VERSION ""

NS_ :

BS_:

BU_: RADAR

BO_ 512 Write_RadarConfig: 8 RADAR
 SG_ MaxDistance_Valid : 0|1@1+ (1,0) [0|1] "Valid" Vector__XXX
 SG_ SensorID_Valid : 1|1@1+ (1,0) [0|1] "Valid" Vector__XXX
 SG_ RadarPower_Valid : 2|1@1+ (1,0) [0|1] "Valid" Vector__XXX
 SG_ OutputType_Valid : 3|1@1+ (1,0) [0|1] "Valid" Vector__XXX
 SG_ SendQuality_Valid : 4|1@1+ (1,0) [0|1] "Valid" Vector__XXX
 SG_ SendExtInfo_Valid : 5|1@1+ (1,0) [0|1] "Valid" Vector__XXX
 SG_ SortIndex_Valid : 6|1@1+ (1,0) [0|1] "Valid" Vector__XXX
 SG_ StoreInNvm_Valid : 7|1@1+ (1,0) [0|1] "Valid" Vector__XXX
 SG_ MaxDistance : 15|10@0+ (1,0) [0|2048] "" XXX
 SG_ SensorID : 32|3@1+ (1,0) [0|7] "ID" Vector__XXX
 SG_ OutputType : 35|2@1+ (1,0) [0|2] "Output Type" Vector__XXX
 SG_ RadarPower : 37|3@1+ (1,0) [0|7] "Power Mode" Vector__XXX
 SG_ SendQuality : 42|1@1+ (1,0) [0|1] "Quality Active" Vector__XXX
 SG_ SendExtInfo : 43|1@1+ (1,0) [0|1] "Extended Info Active" Vector__XXX
 SG_ SortIndex : 44|3@1+ (1,0) [0|7] "Sort Index" Vector__XXX
 SG_ StoreNVM : 47|1@1+ (1,0) [0|1] "Store in NVM" Vector__XXX
 SG_ RCS_Threshold_Valid : 48|1@1+ (1,0) [0|1] "RCS Threshold Valid" Vector__XXX
 SG_ RCS_Threshold : 49|3@1+ (1,0) [0|7] "RCS Threshold" Vector__XXX
 SG_ BaudRate_Valid : 60|1@1+ (1,0) [0|1] "Baud Rate Valid" Vector__XXX
 SG_ BaudRate : 61|3@1+ (1,0) [0|7] "Baud Rate" Vector__XXX

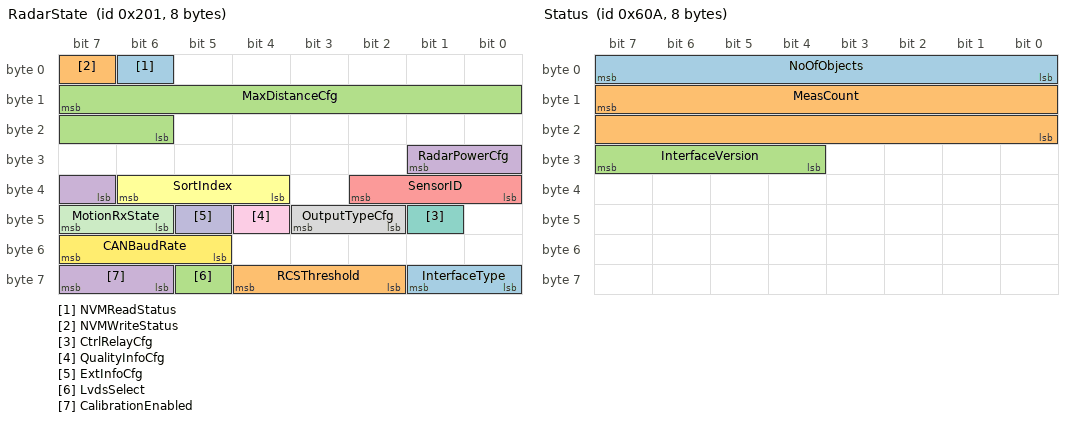
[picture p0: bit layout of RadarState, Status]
BO_ 513 RadarState: 8 RADAR
 SG_ NVMReadStatus : 6|1@0+ (1,0) [0|1] "" XXX
 SG_ NVMWriteStatus : 7|1@0+ (1,0) [0|1] "" XXX
 SG_ MaxDistanceCfg : 15|10@0+ (2,0) [0|2046] "m" XXX
 SG_ RadarPowerCfg : 25|3@0+ (1,0) [0|7] "" XXX
 SG_ SensorID : 34|3@0+ (1,0) [0|7] "" XXX
 SG_ SortIndex : 38|3@0+ (1,0) [0|7] "" XXX
 SG_ CtrlRelayCfg : 41|1@0+ (1,0) [0|1] "" XXX
 SG_ OutputTypeCfg : 43|2@0+ (1,0) [0|3] "" XXX
 SG_ QualityInfoCfg : 44|1@0+ (1,0) [0|1] "" XXX
 SG_ ExtInfoCfg : 45|1@0+ (1,0) [0|1] "" XXX
 SG_ MotionRxState : 46|2@1+ (1,0) [0|3] "" XXX
 SG_ CANBaudRate : 55|3@0+ (1,0) [0|7] "" XXX
 SG_ InterfaceType : 57|2@0+ (1,0) [0|3] "" XXX
 SG_ RCSThreshold : 58|3@1+ (1,0) [0|7] "" XXX
 SG_ LvdsSelect : 61|1@0+ (1,0) [0|1] "" XXX
 SG_ CalibrationEnabled : 63|2@0+ (1,0) [0|3] "" XXX

BO_ 1546 Status: 8 RADAR
 SG_ NoOfObjects : 7|8@0+ (1,0) [0|255] "" XXX
 SG_ MeasCount : 15|16@0+ (1,0) [0|65535] "" XXX
 SG_ InterfaceVersion : 31|4@0+ (1,0) [0|15] "" XXX

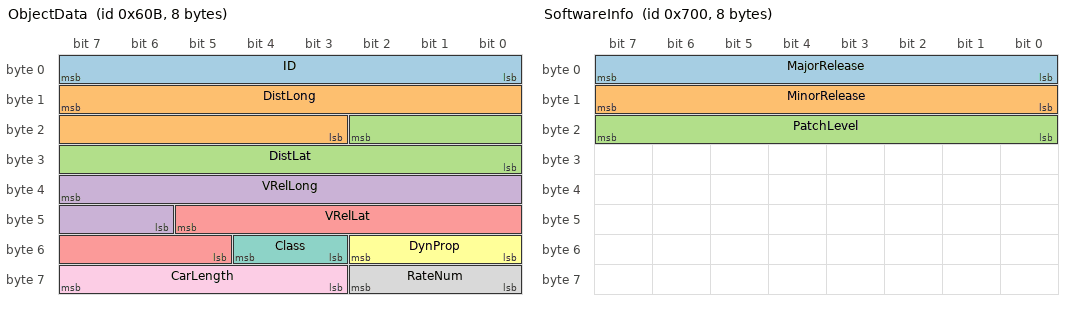
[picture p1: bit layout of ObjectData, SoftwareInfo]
BO_ 1547 ObjectData: 8 RADAR
 SG_ ID : 7|8@0+ (1,0) [0|255] "" XXX
 SG_ DistLong : 15|13@0+ (0.2,-500) [-500|1138.2] "m" XXX
 SG_ DistLat : 18|11@0+ (0.2,-204.6) [-204.6|204.8] "m" XXX
 SG_ VRelLong : 39|10@0+ (0.25,-128) [-128|127.75] "m/s" XXX
 SG_ VRelLat : 45|9@0+ (0.25,-64) [-64|63.75] "m/s" XXX
 SG_ DynProp : 50|3@0+ (1,0) [0|7] "" XXX
 SG_ Class : 52|2@0+ (1,0) [0|3] "" XXX
 SG_ RateNum : 58|3@0+ (1,0) [0|7] "" XXX
 SG_ CarLength : 63|5@0+ (0,0) [-64|63.75] "m" XXX

BO_ 1792 SoftwareInfo: 8 RADAR
 SG_ MajorRelease : 7|8@0+ (1,0) [0|255] "" XXX
 SG_ MinorRelease : 15|8@0+ (1,0) [0|255] "" XXX
 SG_ PatchLevel : 23|8@0+ (1,0) [0|255] "" XXX

CM_ SG_ 512 LVDS "Resereved";
CM_ SG_ 512 CalibrationEnabled "Reserved";
CM_ SG_ 512 CalibrationValid "Reserved";
CM_ BO_ 1547 "Object detection and tracking information";
CM_ SG_ 1547 RateNum "Target Lane Number";
VAL_ 513 NVMReadStatus 0 "Failed" 1 "Successful";
VAL_ 513 NVMWriteStatus 0 "Failed" 1 "Successful";
VAL_ 513 RadarPowerCfg 0 "Standard" 1 "-3dB Gain" 2 "-6dB Gain" 3 "-9dB Gain";
VAL_ 513 SortIndex 0 "No Sorting" 1 "Sort By Range" 2 "Sort By RCS";
VAL_ 513 CtrlRelayCfg 0 "Off" 1 "On";
VAL_ 513 OutputTypeCfg 0 "None" 1 "Objects" 2 "Clusters";
VAL_ 513 QualityInfoCfg 0 "Off" 1 "On";
VAL_ 513 ExtInfoCfg 0 "Off" 1 "On";
VAL_ 513 MotionRxState 0 "input ok" 1 "speed missing" 2 "yaw rate missing" 3 "speed and yaw rate missing";
VAL_ 513 CANBaudRate 0 "500K" 1 "250K" 2 "1M";
VAL_ 513 RCSThreshold 0 "Standard" 1 "High Sensitivity";
VAL_ 513 CalibrationEnabled 1 "Enabled" 2 "Initial Recovery";
VAL_ 1547 DynProp 0 "moving" 1 "stationary" 2 "oncoming" 3 "crossing_left" 4 "crossing_right" 5 "unknown" 6 "stopped";
VAL_ 1547 Class 0 "point" 1 "vehicle" 2 "large vehicle" 3 "motorcycle";
